AUTOSAR XML (schema 3.1.2)
package /Components/SWC_RCD
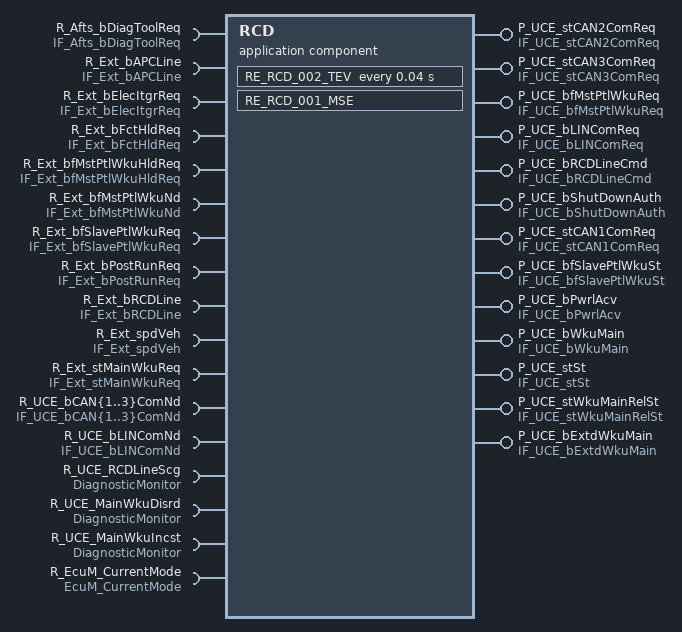
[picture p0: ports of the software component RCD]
  application software component type RCD
    15 x require port:
      R_Afts_bDiagToolReq: unqueued-receiver-com-spec{data-element=Afts_bDiagToolReq, init-value=Afts_bDiagToolReq_in, resync-time=0}, required-interface=IF_Afts_bDiagToolReq
      R_Ext_bAPCLine: unqueued-receiver-com-spec{data-element=Ext_bAPCLine, init-value=Ext_bAPCLine_in, resync-time=0}, required-interface=IF_Ext_bAPCLine
      R_Ext_bElecItgrReq: unqueued-receiver-com-spec{data-element=Ext_bElecItgrReq, init-value=Ext_bElecItgrReq_in, resync-time=0}, required-interface=IF_Ext_bElecItgrReq
      R_Ext_bFctHldReq: unqueued-receiver-com-spec{data-element=Ext_bFctHldReq, init-value=Ext_bFctHldReq_in, resync-time=0}, required-interface=IF_Ext_bFctHldReq
      R_Ext_bfMstPtlWkuHldReq: unqueued-receiver-com-spec{data-element=Ext_bfMstPtlWkuHldReq, init-value=Ext_bfMstPtlWkuHldReq_in, resync-time=0}, required-interface=IF_Ext_bfMstPtlWkuHldReq
      R_Ext_bfMstPtlWkuNd: unqueued-receiver-com-spec{data-element=Ext_bfMstPtlWkuNd, init-value=Ext_bfMstPtlWkuNd_in, resync-time=0}, required-interface=IF_Ext_bfMstPtlWkuNd
      R_Ext_bfSlavePtlWkuReq: unqueued-receiver-com-spec{data-element=Ext_bfSlavePtlWkuReq, init-value=Ext_bfSlavePtlWkuReq_in, resync-time=0}, required-interface=IF_Ext_bfSlavePtlWkuReq
      R_Ext_bPostRunReq: unqueued-receiver-com-spec{data-element=Ext_bPostRunReq, init-value=Ext_bPostRunReq_in, resync-time=0}, required-interface=IF_Ext_bPostRunReq
      R_Ext_bRCDLine: unqueued-receiver-com-spec{data-element=Ext_bRCDLine, init-value=Ext_bRCDLine_in, resync-time=0}, required-interface=IF_Ext_bRCDLine
      R_Ext_spdVeh: unqueued-receiver-com-spec{data-element=Ext_spdVeh, init-value=ConstantValue, resync-time=0}, required-interface=IF_Ext_spdVeh
      R_Ext_stMainWkuReq: unqueued-receiver-com-spec{data-element=Ext_stMainWkuReq, init-value=Ext_stMainWkuReq_in, resync-time=0}, required-interface=IF_Ext_stMainWkuReq
      R_UCE_bCAN{1..3}ComNd: unqueued-receiver-com-spec{data-element=UCE_bCAN{1..3}ComNd, init-value=UCE_bCAN{1..3}ComNd_in, resync-time=0}, required-interface=IF_UCE_bCAN{1..3}ComNd
      R_UCE_bLINComNd: unqueued-receiver-com-spec{data-element=UCE_bLINComNd, init-value=UCE_bLINComNd_in, resync-time=0}, required-interface=IF_UCE_bLINComNd
    10 x provide port:
      P_UCE_stCAN2ComReq: unqueued-sender-com-spec{data-element=UCE_stCAN2ComReq, can-invalidate=false, init-value=UCE_stCAN2ComReq_out}, provided-interface=IF_UCE_stCAN2ComReq
      P_UCE_stCAN3ComReq: unqueued-sender-com-spec{data-element=UCE_stCAN3ComReq, can-invalidate=false, init-value=UCE_stCAN3ComReq_out}, provided-interface=IF_UCE_stCAN3ComReq
      P_UCE_bfMstPtlWkuReq: unqueued-sender-com-spec{data-element=UCE_bfMstPtlWkuReq, can-invalidate=false, init-value=UCE_bfMstPtlWkuReq_out}, provided-interface=IF_UCE_bfMstPtlWkuReq
      P_UCE_bLINComReq: unqueued-sender-com-spec{data-element=UCE_bLINComReq, can-invalidate=false, init-value=UCE_bLINComReq_out}, provided-interface=IF_UCE_bLINComReq
      P_UCE_bRCDLineCmd: unqueued-sender-com-spec{data-element=UCE_bRCDLineCmd, can-invalidate=false, init-value=UCE_bRCDLineCmd_out}, provided-interface=IF_UCE_bRCDLineCmd
      P_UCE_bShutDownAuth: unqueued-sender-com-spec{data-element=UCE_bShutDownAuth, can-invalidate=false, init-value=UCE_bShutDownAuth_out}, provided-interface=IF_UCE_bShutDownAuth
      P_UCE_stCAN1ComReq: unqueued-sender-com-spec{data-element=UCE_stCAN1ComReq, can-invalidate=false, init-value=UCE_stCAN1ComReq_out}, provided-interface=IF_UCE_stCAN1ComReq
      P_UCE_bfSlavePtlWkuSt: unqueued-sender-com-spec{data-element=UCE_bfSlavePtlWkuSt, can-invalidate=false, init-value=UCE_bfSlavePtlWkuSt_out}, provided-interface=IF_UCE_bfSlavePtlWkuSt
      P_UCE_bPwrlAcv: unqueued-sender-com-spec{data-element=UCE_bPwrlAcv, can-invalidate=false, init-value=UCE_bPwrlAcv_out}, provided-interface=IF_UCE_bPwrlAcv
      P_UCE_bWkuMain: unqueued-sender-com-spec{data-element=UCE_bWkuMain, can-invalidate=false, init-value=UCE_bWkuMain_out}, provided-interface=IF_UCE_bWkuMain
    4 x require port:
      R_UCE_RCDLineScg: required-interface=DiagnosticMonitor
      R_UCE_MainWkuDisrd: required-interface=DiagnosticMonitor
      R_UCE_MainWkuIncst: required-interface=DiagnosticMonitor
      R_EcuM_CurrentMode: required-interface=EcuM_CurrentMode
    provide port P_UCE_stSt: provided-interface=IF_UCE_stSt  # UCE_stSt
    provide port P_UCE_stWkuMainRelSt: provided-interface=IF_UCE_stWkuMainRelSt
    provide port P_UCE_bExtdWkuMain: unqueued-sender-com-spec{data-element=UCE_bExtdWkuMain, can-invalidate=false, init-value=UCE_bPwrlAcv_out1}, provided-interface=IF_UCE_bExtdWkuMain
  26 x constant specification:
    Afts_bDiagToolReq_in
      value:
        boolean literal Afts_bDiagToolReq_in: type=DT_Afts_bDiagToolReq, value=false
    ConstantValue
      value:
        integer literal ConstantValue: type=DT_Ext_spdVeh, value=0
    Ext_bAPCLine_in
      value:
        boolean literal Ext_bAPCLine_in: type=DT_Ext_bAPCLine, value=false
    Ext_bElecItgrReq_in
      value:
        boolean literal Ext_bElecItgrReq_in: type=DT_Ext_bElecItgrReq, value=false
    Ext_bFctHldReq_in
      value:
        boolean literal Ext_bFctHldReq_in: type=DT_Ext_bFctHldReq, value=false
    Ext_bfMstPtlWkuHldReq_in
      value:
        integer literal Ext_bfMstPtlWkuHldReq_in: type=DT_Ext_bfMstPtlWkuHldReq, value=0
    Ext_bfMstPtlWkuNd_in
      value:
        integer literal Ext_bfMstPtlWkuNd_in: type=DT_Ext_bfMstPtlWkuNd, value=0
    Ext_bfSlavePtlWkuReq_in
      value:
        integer literal Ext_bfSlavePtlWkuReq_in: type=DT_Ext_bfSlavePtlWkuReq, value=0
    Ext_bPostRunReq_in
      value:
        boolean literal Ext_bPostRunReq_in: type=DT_Ext_bPostRunReq, value=false
    Ext_bRCDLine_in
      value:
        boolean literal Ext_bRCDLine_in: type=DT_Ext_bRCDLine, value=false
    Ext_stMainWkuReq_in
      value:
        integer literal Ext_stMainWkuReq_in: type=DT_Ext_stMainWkuReq, value=0
    UCE_bCAN1ComNd_in
      value:
        boolean literal UCE_bCAN1ComNd_in: type=DT_UCE_bCAN1ComNd, value=false
    UCE_bCAN2ComNd_in
      value:
        boolean literal UCE_bCAN2ComNd_in: type=DT_UCE_bCAN2ComNd, value=false
    UCE_bCAN3ComNd_in
      value:
        boolean literal UCE_bCAN3ComNd_in: type=DT_UCE_bCAN3ComNd, value=false
    UCE_bfMstPtlWkuReq_out
      value:
        integer literal UCE_bfMstPtlWkuReq_out: type=DT_UCE_bfMstPtlWkuReq, value=0
    UCE_bfSlavePtlWkuSt_out
      value:
        integer literal UCE_bfSlavePtlWkuSt_out: type=DT_UCE_bfSlavePtlWkuSt, value=0
    UCE_bLINComNd_in
      value:
        boolean literal UCE_bLINComNd_in: type=DT_UCE_bLINComNd, value=false
    UCE_bLINComReq_out
      value:
        boolean literal UCE_bLINComReq_out: type=DT_UCE_bLINComReq, value=false
    UCE_bPwrlAcv_out
      value:
        boolean literal UCE_bPwrlAcv_out: type=DT_UCE_bPwrlAcv, value=false
    UCE_bPwrlAcv_out1
      value:
        boolean literal UCE_bPwrlAcv_out1: type=DT_UCE_bExtdWkuMain, value=false
    UCE_bRCDLineCmd_out
      value:
        boolean literal UCE_bRCDLineCmd_out: type=DT_UCE_bRCDLineCmd, value=false
    UCE_bShutDownAuth_out
      value:
        boolean literal UCE_bShutDownAuth_out: type=DT_UCE_bShutDownAuth, value=false
    UCE_bWkuMain_out
      value:
        boolean literal UCE_bWkuMain_out: type=DT_UCE_bWkuMain, value=false
    UCE_stCAN1ComReq_out
      value:
        integer literal UCE_stCAN1ComReq_out: type=DT_UCE_stCAN1ComReq, value=0
    UCE_stCAN2ComReq_out
      value:
        integer literal UCE_stCAN2ComReq_out: type=DT_UCE_stCAN2ComReq, value=0
    UCE_stCAN3ComReq_out
      value:
        integer literal UCE_stCAN3ComReq_out: type=DT_UCE_stCAN3ComReq, value=0
  internal behavior IB_RCD: component=RCD
    timing event EV_RCD_002_TEV: mode-dependency=dependent-on-mode=[R_EcuM_CurrentMode.currentMode.SLEEP, R_EcuM_CurrentMode.currentMode.WAKE_SLEEP, R_EcuM_CurrentMode.currentMode.SHUTDOWN, R_EcuM_CurrentMode.currentMode.STARTUP, R_EcuM_CurrentMode.currentMode.POST_RUN], start-on-event=RE_RCD_002_TEV, period=0.04
    mode switch event EV_RCD_001_MSE: start-on-event=RE_RCD_001_MSE, activation=ENTRY, mode=R_EcuM_CurrentMode.currentMode.RUN
    runnable RE_RCD_002_TEV
      15 x data receive point:
        dr_Ext_bfMstPtlWkuHldReq: data-element=R_Ext_bfMstPtlWkuHldReq.Ext_bfMstPtlWkuHldReq
        dr_Ext_stMainWkuReq: data-element=R_Ext_stMainWkuReq.Ext_stMainWkuReq
        dr_UCE_bCAN2ComNd: data-element=R_UCE_bCAN2ComNd.UCE_bCAN2ComNd
        dr_Ext_bfSlavePtlWkuReq: data-element=R_Ext_bfSlavePtlWkuReq.Ext_bfSlavePtlWkuReq
        dr_UCE_bCAN1ComNd: data-element=R_UCE_bCAN1ComNd.UCE_bCAN1ComNd
        dr_Ext_bElecItgrReq: data-element=R_Ext_bElecItgrReq.Ext_bElecItgrReq
        dr_Ext_bPostRunReq: data-element=R_Ext_bPostRunReq.Ext_bPostRunReq
        dr_Ext_bfMstPtlWkuNd: data-element=R_Ext_bfMstPtlWkuNd.Ext_bfMstPtlWkuNd
        dr_Ext_bFctHldReq: data-element=R_Ext_bFctHldReq.Ext_bFctHldReq
        dr_UCE_bCAN3ComNd: data-element=R_UCE_bCAN3ComNd.UCE_bCAN3ComNd
        dr_Ext_bAPCLine: data-element=R_Ext_bAPCLine.Ext_bAPCLine
        dr_Afts_bDiagToolReq: data-element=R_Afts_bDiagToolReq.Afts_bDiagToolReq
        dr_Ext_bRCDLine: data-element=R_Ext_bRCDLine.Ext_bRCDLine
        dr_UCE_bLINComNd: data-element=R_UCE_bLINComNd.UCE_bLINComNd
        dr_Ext_spdVeh: data-element=R_Ext_spdVeh.Ext_spdVeh
      11 x data send point:
        ds_UCE_bLINComReq: data-element=P_UCE_bLINComReq.UCE_bLINComReq
        ds_UCE_stCAN3ComReq: data-element=P_UCE_stCAN3ComReq.UCE_stCAN3ComReq
        ds_UCE_bfSlavePtlWkuSt: data-element=P_UCE_bfSlavePtlWkuSt.UCE_bfSlavePtlWkuSt
        ds_UCE_stCAN2ComReq: data-element=P_UCE_stCAN2ComReq.UCE_stCAN2ComReq
        ds_UCE_stCAN1ComReq: data-element=P_UCE_stCAN1ComReq.UCE_stCAN1ComReq
        ds_UCE_bfMstPtlWkuReq: data-element=P_UCE_bfMstPtlWkuReq.UCE_bfMstPtlWkuReq
        ds_UCE_bPwrlAcv: data-element=P_UCE_bPwrlAcv.UCE_bPwrlAcv
        ds_UCE_bRCDLineCmd: data-element=P_UCE_bRCDLineCmd.UCE_bRCDLineCmd
        ds_UCE_bExtdWkuMain: data-element=P_UCE_bExtdWkuMain.UCE_bExtdWkuMain
        ds_UCE_bShutDownAuth: data-element=P_UCE_bShutDownAuth.UCE_bShutDownAuth
        ds_UCE_bWkuMain: data-element=P_UCE_bWkuMain.UCE_bWkuMain
      mode switch point ms_UCE_stWkuMainRelSt: mode-group=P_UCE_stWkuMainRelSt.RCD_stWkuMainRelSt
      mode switch point ms_UCE_stSt: mode-group=P_UCE_stSt.RCD_Mode
      sync call scp_Dem_SetEventStatus13: operation=R_UCE_MainWkuIncst.SetEventStatus
      sync call scp_Dem_SetEventStatus11: operation=R_UCE_RCDLineScg.SetEventStatus
      sync call scp_Dem_SetEventStatus12: operation=R_UCE_MainWkuDisrd.SetEventStatus
    runnable RE_RCD_001_MSE
      11 x data send point:
        ds_UCE_bPwrlAcv: data-element=P_UCE_bPwrlAcv.UCE_bPwrlAcv
        ds_UCE_bfMstPtlWkuReq: data-element=P_UCE_bfMstPtlWkuReq.UCE_bfMstPtlWkuReq
        ds_UCE_stCAN1ComReq: data-element=P_UCE_stCAN1ComReq.UCE_stCAN1ComReq
        ds_UCE_stCAN3ComReq: data-element=P_UCE_stCAN3ComReq.UCE_stCAN3ComReq
        ds_UCE_bRCDLineCmd: data-element=P_UCE_bRCDLineCmd.UCE_bRCDLineCmd
        ds_UCE_bShutDownAuth: data-element=P_UCE_bShutDownAuth.UCE_bShutDownAuth
        ds_UCE_bfSlavePtlWkuSt: data-element=P_UCE_bfSlavePtlWkuSt.UCE_bfSlavePtlWkuSt
        ds_UCE_stCAN2ComReq: data-element=P_UCE_stCAN2ComReq.UCE_stCAN2ComReq
        ds_UCE_bExtdWkuMain: data-element=P_UCE_bExtdWkuMain.UCE_bExtdWkuMain
        ds_UCE_bWkuMain: data-element=P_UCE_bWkuMain.UCE_bWkuMain
        ds_UCE_bLINComReq: data-element=P_UCE_bLINComReq.UCE_bLINComReq
  swc implementation Imp_RCD: programming-language=C, behavior=IB_RCD
    code-descriptors:
      code CodeDescriptor: type=SRC
        7 x xfile:
          RCD_002_TEV_fct_c: url=RCD_002_TEV_fct.c
          RCD_calibrations_h: url=RCD_calibrations.h
          RCD_MemMap_h: url=RCD_MemMap.h
          RCD_c: url=RCD.c
          RCD_calibrations_c: url=RCD_calibrations.c
          RCD_h: url=RCD.h
          RCD_002_TEV_fct_h: url=RCD_002_TEV_fct.h
